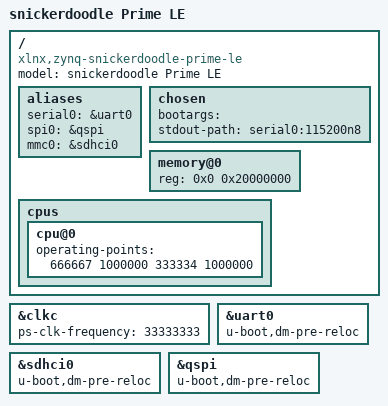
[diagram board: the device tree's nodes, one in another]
/*
 * snickerdoodle Prime LE board DTS
 *
 * Copyright (c) 2017 krtkl inc.
 *
 * SPDX-License-Identifier:     GPL-2.0+
 */


/dts-v1/;
/include/ "zynq-7000.dtsi"
/ {
        model = "snickerdoodle Prime LE";
        compatible = "xlnx,zynq-snickerdoodle-prime-le", "xlnx,zynq-7000";

	aliases {
		serial0 = &uart0;
		spi0 = &qspi;
		mmc0 = &sdhci0;
	};

	chosen {
		bootargs = "";
                stdout-path = "serial0:115200n8";
	};

	memory@0 {
		device_type = "memory";
		reg = <0x0 0x20000000>;
	};

	cpus {
		cpu@0 {
			operating-points = <
				/* kHz	uV */
				666667	1000000
				333334	1000000
			>;
		};
	};
};

&clkc {
	ps-clk-frequency = <33333333>;
};

&uart0 {
	u-boot,dm-pre-reloc;
        status = "okay";
};

&sdhci0 {
	u-boot,dm-pre-reloc;
        status = "okay";
};

&qspi {
	u-boot,dm-pre-reloc;
	status = "okay";
};
